AUTOSAR XML (schema 00046)
package /ComponentTypes
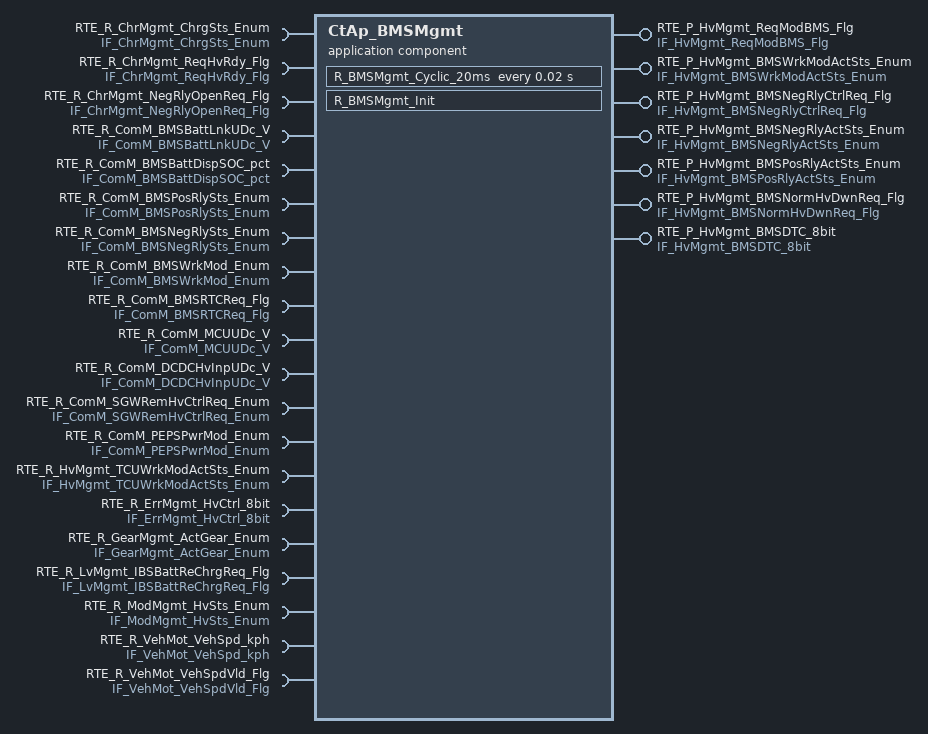
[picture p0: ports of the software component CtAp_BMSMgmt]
  application sw component type CtAp_BMSMgmt
    7 x provide port:
      RTE_P_HvMgmt_ReqModBMS_Flg: nonqueued-sender-com-spec{data-element=tec_HvMgmt_ReqModBMS_Flg, init-value=0}, provided-interface=IF_HvMgmt_ReqModBMS_Flg
      RTE_P_HvMgmt_BMSWrkModActSts_Enum: nonqueued-sender-com-spec{data-element=tec_HvMgmt_BMSWrkModActSts_Enum, init-value=0}, provided-interface=IF_HvMgmt_BMSWrkModActSts_Enum
      RTE_P_HvMgmt_BMSNegRlyCtrlReq_Flg: nonqueued-sender-com-spec{data-element=tec_HvMgmt_BMSNegRlyCtrlReq_Flg, init-value=0}, provided-interface=IF_HvMgmt_BMSNegRlyCtrlReq_Flg
      RTE_P_HvMgmt_BMSNegRlyActSts_Enum: nonqueued-sender-com-spec{data-element=tec_HvMgmt_BMSNegRlyActSts_Enum, init-value=0}, provided-interface=IF_HvMgmt_BMSNegRlyActSts_Enum
      RTE_P_HvMgmt_BMSPosRlyActSts_Enum: nonqueued-sender-com-spec{data-element=tec_HvMgmt_BMSPosRlyActSts_Enum, init-value=0}, provided-interface=IF_HvMgmt_BMSPosRlyActSts_Enum
      RTE_P_HvMgmt_BMSNormHvDwnReq_Flg: nonqueued-sender-com-spec{data-element=tec_HvMgmt_BMSNormHvDwnReq_Flg, init-value=0}, provided-interface=IF_HvMgmt_BMSNormHvDwnReq_Flg
      RTE_P_HvMgmt_BMSDTC_8bit: nonqueued-sender-com-spec{data-element=tec_HvMgmt_BMSDTC_8bit, init-value=0}, provided-interface=IF_HvMgmt_BMSDTC_8bit
    20 x require port:
      RTE_R_ChrMgmt_ChrgSts_Enum: nonqueued-receiver-com-spec{data-element=tec_ChrMgmt_ChrgSts_Enum, filter=data-filter-type=ALWAYS, init-value=0}, required-interface=IF_ChrMgmt_ChrgSts_Enum
      RTE_R_ChrMgmt_ReqHvRdy_Flg: nonqueued-receiver-com-spec{data-element=tec_ChrMgmt_ReqHvRdy_Flg, filter=data-filter-type=ALWAYS, init-value=0}, required-interface=IF_ChrMgmt_ReqHvRdy_Flg
      RTE_R_ChrMgmt_NegRlyOpenReq_Flg: nonqueued-receiver-com-spec{data-element=tec_ChrMgmt_NegRlyOpenReq_Flg, filter=data-filter-type=ALWAYS, init-value=0}, required-interface=IF_ChrMgmt_NegRlyOpenReq_Flg
      RTE_R_ComM_BMSBattLnkUDc_V: nonqueued-receiver-com-spec{data-element=tec_ComM_BMSBattLnkUDc_V, filter=data-filter-type=ALWAYS, init-value=0}, required-interface=IF_ComM_BMSBattLnkUDc_V
      RTE_R_ComM_BMSBattDispSOC_pct: nonqueued-receiver-com-spec{data-element=tec_ComM_BMSBattDispSOC_pct, filter=data-filter-type=ALWAYS, init-value=0}, required-interface=IF_ComM_BMSBattDispSOC_pct
      RTE_R_ComM_BMSPosRlySts_Enum: nonqueued-receiver-com-spec{data-element=tec_ComM_BMSPosRlySts_Enum, filter=data-filter-type=ALWAYS, init-value=0}, required-interface=IF_ComM_BMSPosRlySts_Enum
      RTE_R_ComM_BMSNegRlySts_Enum: nonqueued-receiver-com-spec{data-element=tec_ComM_BMSNegRlySts_Enum, filter=data-filter-type=ALWAYS, init-value=0}, required-interface=IF_ComM_BMSNegRlySts_Enum
      RTE_R_ComM_BMSWrkMod_Enum: nonqueued-receiver-com-spec{data-element=tec_ComM_BMSWrkMod_Enum, filter=data-filter-type=ALWAYS, init-value=0}, required-interface=IF_ComM_BMSWrkMod_Enum
      RTE_R_ComM_BMSRTCReq_Flg: nonqueued-receiver-com-spec{data-element=tec_ComM_BMSRTCReq_Flg, filter=data-filter-type=ALWAYS, init-value=0}, required-interface=IF_ComM_BMSRTCReq_Flg
      RTE_R_ComM_MCUUDc_V: nonqueued-receiver-com-spec{data-element=tec_ComM_MCUUDc_V, filter=data-filter-type=ALWAYS, init-value=0}, required-interface=IF_ComM_MCUUDc_V
      RTE_R_ComM_DCDCHvInpUDc_V: nonqueued-receiver-com-spec{data-element=tec_ComM_DCDCHvInpUDc_V, filter=data-filter-type=ALWAYS, init-value=0}, required-interface=IF_ComM_DCDCHvInpUDc_V
      RTE_R_ComM_SGWRemHvCtrlReq_Enum: nonqueued-receiver-com-spec{data-element=tec_ComM_SGWRemHvCtrlReq_Enum, filter=data-filter-type=ALWAYS, init-value=0}, required-interface=IF_ComM_SGWRemHvCtrlReq_Enum
      RTE_R_ComM_PEPSPwrMod_Enum: nonqueued-receiver-com-spec{data-element=tec_ComM_PEPSPwrMod_Enum, filter=data-filter-type=ALWAYS, init-value=0}, required-interface=IF_ComM_PEPSPwrMod_Enum
      RTE_R_HvMgmt_TCUWrkModActSts_Enum: nonqueued-receiver-com-spec{data-element=tec_HvMgmt_TCUWrkModActSts_Enum, filter=data-filter-type=ALWAYS, init-value=0}, required-interface=IF_HvMgmt_TCUWrkModActSts_Enum
      RTE_R_ErrMgmt_HvCtrl_8bit: nonqueued-receiver-com-spec{data-element=tec_ErrMgmt_HvCtrl_8bit, filter=data-filter-type=ALWAYS, init-value=0}, required-interface=IF_ErrMgmt_HvCtrl_8bit
      RTE_R_GearMgmt_ActGear_Enum: nonqueued-receiver-com-spec{data-element=tec_GearMgmt_ActGear_Enum, filter=data-filter-type=ALWAYS, init-value=0}, required-interface=IF_GearMgmt_ActGear_Enum
      RTE_R_LvMgmt_IBSBattReChrgReq_Flg: nonqueued-receiver-com-spec{data-element=tec_LvMgmt_IBSBattReChrgReq_Flg, filter=data-filter-type=ALWAYS, init-value=0}, required-interface=IF_LvMgmt_IBSBattReChrgReq_Flg
      RTE_R_ModMgmt_HvSts_Enum: nonqueued-receiver-com-spec{data-element=tec_ModMgmt_HvSts_Enum, filter=data-filter-type=ALWAYS, init-value=0}, required-interface=IF_ModMgmt_HvSts_Enum
      RTE_R_VehMot_VehSpd_kph: nonqueued-receiver-com-spec{data-element=tec_VehMot_VehSpd_kph, filter=data-filter-type=ALWAYS, init-value=0}, required-interface=IF_VehMot_VehSpd_kph
      RTE_R_VehMot_VehSpdVld_Flg: nonqueued-receiver-com-spec{data-element=tec_VehMot_VehSpdVld_Flg, filter=data-filter-type=ALWAYS, init-value=0}, required-interface=IF_VehMot_VehSpdVld_Flg
    behavior CtAp_BMSMgmt_InternalBehavior
      init event CtAp_BMSMgmt_InitEvent: start-on-event=R_BMSMgmt_Init
      timing event TMT_R_BMSMgmt_Cyclic_20ms: start-on-event=R_BMSMgmt_Cyclic_20ms, period=0.02
      runnable R_BMSMgmt_Init
      runnable R_BMSMgmt_Cyclic_20ms
        data-receive-point-by-arguments:
          20 x access:
            REC_RTE_R_ChrMgmt_ChrgSts_Enum_tec_ChrMgmt_ChrgSts_Enum: accessed-variable=RTE_R_ChrMgmt_ChrgSts_Enum.tec_ChrMgmt_ChrgSts_Enum
            REC_RTE_R_ChrMgmt_NegRlyOpenReq_Flg_tec_ChrMgmt_NegRlyOpenReq_Flg: accessed-variable=RTE_R_ChrMgmt_NegRlyOpenReq_Flg.tec_ChrMgmt_NegRlyOpenReq_Flg
            REC_RTE_R_ChrMgmt_ReqHvRdy_Flg_tec_ChrMgmt_ReqHvRdy_Flg: accessed-variable=RTE_R_ChrMgmt_ReqHvRdy_Flg.tec_ChrMgmt_ReqHvRdy_Flg
            REC_RTE_R_ComM_BMSBattDispSOC_pct_tec_ComM_BMSBattDispSOC_pct: accessed-variable=RTE_R_ComM_BMSBattDispSOC_pct.tec_ComM_BMSBattDispSOC_pct
            REC_RTE_R_ComM_BMSBattLnkUDc_V_tec_ComM_BMSBattLnkUDc_V: accessed-variable=RTE_R_ComM_BMSBattLnkUDc_V.tec_ComM_BMSBattLnkUDc_V
            REC_RTE_R_ComM_BMSNegRlySts_Enum_tec_ComM_BMSNegRlySts_Enum: accessed-variable=RTE_R_ComM_BMSNegRlySts_Enum.tec_ComM_BMSNegRlySts_Enum
            REC_RTE_R_ComM_BMSPosRlySts_Enum_tec_ComM_BMSPosRlySts_Enum: accessed-variable=RTE_R_ComM_BMSPosRlySts_Enum.tec_ComM_BMSPosRlySts_Enum
            REC_RTE_R_ComM_BMSRTCReq_Flg_tec_ComM_BMSRTCReq_Flg: accessed-variable=RTE_R_ComM_BMSRTCReq_Flg.tec_ComM_BMSRTCReq_Flg
            REC_RTE_R_ComM_BMSWrkMod_Enum_tec_ComM_BMSWrkMod_Enum: accessed-variable=RTE_R_ComM_BMSWrkMod_Enum.tec_ComM_BMSWrkMod_Enum
            REC_RTE_R_ComM_DCDCHvInpUDc_V_tec_ComM_DCDCHvInpUDc_V: accessed-variable=RTE_R_ComM_DCDCHvInpUDc_V.tec_ComM_DCDCHvInpUDc_V
            REC_RTE_R_ComM_MCUUDc_V_tec_ComM_MCUUDc_V: accessed-variable=RTE_R_ComM_MCUUDc_V.tec_ComM_MCUUDc_V
            REC_RTE_R_ComM_PEPSPwrMod_Enum_tec_ComM_PEPSPwrMod_Enum: accessed-variable=RTE_R_ComM_PEPSPwrMod_Enum.tec_ComM_PEPSPwrMod_Enum
            REC_RTE_R_ComM_SGWRemHvCtrlReq_Enum_tec_ComM_SGWRemHvCtrlReq_Enum: accessed-variable=RTE_R_ComM_SGWRemHvCtrlReq_Enum.tec_ComM_SGWRemHvCtrlReq_Enum
            REC_RTE_R_HvMgmt_TCUWrkModActSts_Enum_tec_HvMgmt_TCUWrkModActSts_Enum: accessed-variable=RTE_R_HvMgmt_TCUWrkModActSts_Enum.tec_HvMgmt_TCUWrkModActSts_Enum
            REC_RTE_R_ErrMgmt_HvCtrl_8bit_tec_ErrMgmt_HvCtrl_8bit: accessed-variable=RTE_R_ErrMgmt_HvCtrl_8bit.tec_ErrMgmt_HvCtrl_8bit
            REC_RTE_R_GearMgmt_ActGear_Enum_tec_GearMgmt_ActGear_Enum: accessed-variable=RTE_R_GearMgmt_ActGear_Enum.tec_GearMgmt_ActGear_Enum
            REC_RTE_R_LvMgmt_IBSBattReChrgReq_Flg_tec_LvMgmt_IBSBattReChrgReq_Flg: accessed-variable=RTE_R_LvMgmt_IBSBattReChrgReq_Flg.tec_LvMgmt_IBSBattReChrgReq_Flg
            REC_RTE_R_ModMgmt_HvSts_Enum_tec_ModMgmt_HvSts_Enum: accessed-variable=RTE_R_ModMgmt_HvSts_Enum.tec_ModMgmt_HvSts_Enum
            REC_RTE_R_VehMot_VehSpdVld_Flg_tec_VehMot_VehSpdVld_Flg: accessed-variable=RTE_R_VehMot_VehSpdVld_Flg.tec_VehMot_VehSpdVld_Flg
            REC_RTE_R_VehMot_VehSpd_kph_tec_VehMot_VehSpd_kph: accessed-variable=RTE_R_VehMot_VehSpd_kph.tec_VehMot_VehSpd_kph
        data-send-points:
          7 x access:
            SEND_RTE_P_HvMgmt_BMSDTC_8bit_tec_HvMgmt_BMSDTC_8bit: accessed-variable=RTE_P_HvMgmt_BMSDTC_8bit.tec_HvMgmt_BMSDTC_8bit
            SEND_RTE_P_HvMgmt_BMSNegRlyActSts_Enum_tec_HvMgmt_BMSNegRlyActSts_Enum: accessed-variable=RTE_P_HvMgmt_BMSNegRlyActSts_Enum.tec_HvMgmt_BMSNegRlyActSts_Enum
            SEND_RTE_P_HvMgmt_BMSNegRlyCtrlReq_Flg_tec_HvMgmt_BMSNegRlyCtrlReq_Flg: accessed-variable=RTE_P_HvMgmt_BMSNegRlyCtrlReq_Flg.tec_HvMgmt_BMSNegRlyCtrlReq_Flg
            SEND_RTE_P_HvMgmt_BMSNormHvDwnReq_Flg_tec_HvMgmt_BMSNormHvDwnReq_Flg: accessed-variable=RTE_P_HvMgmt_BMSNormHvDwnReq_Flg.tec_HvMgmt_BMSNormHvDwnReq_Flg
            SEND_RTE_P_HvMgmt_BMSPosRlyActSts_Enum_tec_HvMgmt_BMSPosRlyActSts_Enum: accessed-variable=RTE_P_HvMgmt_BMSPosRlyActSts_Enum.tec_HvMgmt_BMSPosRlyActSts_Enum
            SEND_RTE_P_HvMgmt_BMSWrkModActSts_Enum_tec_HvMgmt_BMSWrkModActSts_Enum: accessed-variable=RTE_P_HvMgmt_BMSWrkModActSts_Enum.tec_HvMgmt_BMSWrkModActSts_Enum
            SEND_RTE_P_HvMgmt_ReqModBMS_Flg_tec_HvMgmt_ReqModBMS_Flg: accessed-variable=RTE_P_HvMgmt_ReqModBMS_Flg.tec_HvMgmt_ReqModBMS_Flg
  swc implementation CtAp_BMSMgmt_Implementation: behavior=CtAp_BMSMgmt_InternalBehavior
    code-descriptors:
      code Default: artifact-descriptors=autosar-engineering-object=category=SWOBJ
